# wiz16b8m4ct3_0_WIZ16B8M4CT3 register map
Vendor: Texas Instruments
Registers are 32-bit, read-write, reset 0x0 unless marked. A register's access mark holds for its fields unless they carry their own. Offsets are as the file gives them; [hi:lo] are bit positions; {n}, {i} and the like mark numbered series.

## wiz16b8m4ct3_0_WIZ16B8M4CT3 (part 7 of 12)
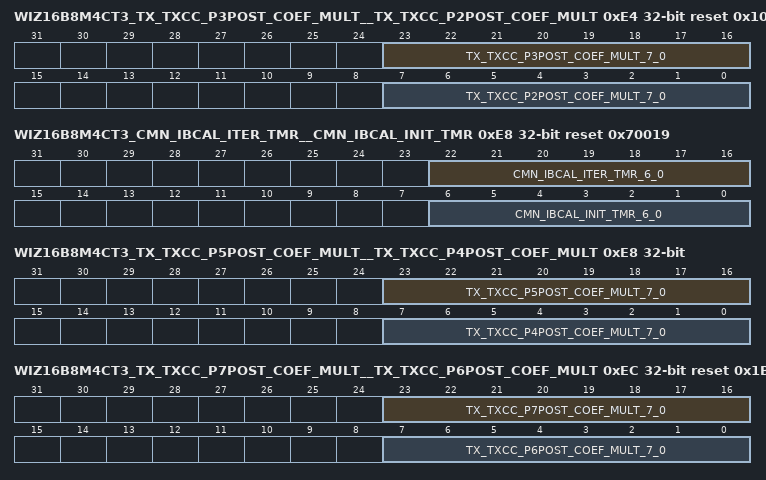
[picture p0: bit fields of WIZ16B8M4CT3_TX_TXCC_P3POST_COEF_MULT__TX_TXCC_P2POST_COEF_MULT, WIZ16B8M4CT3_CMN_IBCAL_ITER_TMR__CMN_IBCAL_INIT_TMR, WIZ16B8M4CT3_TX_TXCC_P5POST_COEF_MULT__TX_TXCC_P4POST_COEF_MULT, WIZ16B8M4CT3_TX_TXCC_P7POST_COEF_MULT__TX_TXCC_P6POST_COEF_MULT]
0xE4 WIZ16B8M4CT3_TX_TXCC_P3POST_COEF_MULT__TX_TXCC_P2POST_COEF_MULT reset 0x10001B
  [23:16] TX_TXCC_P3POST_COEF_MULT_7_0 — Preset 3 post emphasis coefficient multiplier value : The value in this field specifies the multiplier value used to generate the preset 3 post emphasis coefficient value from the FS value. The following describes the multiplier value each bit in this field corresponds to. Bit 7 : 128/128 = 1.000000 Bit 6 : 64/128 = 0.500000 Bit 5 : 32/128 = 0.250000 Bit 4 : 16/128 = 0.125000 Bit 3 : 8/128 = 0.062500 Bit 2 : 4/128 = 0.031250 Bit 1 : 2/128 = 0.015625 Bit 0 : 1/128 = 0.0078125 Note: The output of the multiplier is 6 bits wide. It is possible to set the multiplier value here to a sufficiently large value to cause the multiplier result to be such that it can't be represented by a 6 bit value. In such a case, the multiplier output will be driven to 6'b111111.
  [7:0] TX_TXCC_P2POST_COEF_MULT_7_0 — Preset 2 post emphasis coefficient multiplier value : The value in this field specifies the multiplier value used to generate the preset 2 post emphasis coefficient value from the FS value. The following describes the multiplier value each bit in this field corresponds to. Bit 7 : 128/128 = 1.000000 Bit 6 : 64/128 = 0.500000 Bit 5 : 32/128 = 0.250000 Bit 4 : 16/128 = 0.125000 Bit 3 : 8/128 = 0.062500 Bit 2 : 4/128 = 0.031250 Bit 1 : 2/128 = 0.015625 Bit 0 : 1/128 = 0.0078125 Note: The output of the multiplier is 6 bits wide. It is possible to set the multiplier value here to a sufficiently large value to cause the multiplier result to be such that it can't be represented by a 6 bit value. In such a case, the multiplier output will be driven to 6'b111111.
0xE8 WIZ16B8M4CT3_CMN_IBCAL_ITER_TMR__CMN_IBCAL_INIT_TMR reset 0x70019
  [22:16] CMN_IBCAL_ITER_TMR_6_0 — Iteration wait timer value: This is the number of cmn_ref_clk clocks to wait between when a value is placed on the calibration selection bus going to the analog, and when the comparator value coming from the analog circuits can be checked. Note: This should never be set to a value of less than 3.
  [6:0] CMN_IBCAL_INIT_TMR_6_0 — Initialization wait timer value: This is the number of cmn_ref_clk clocks to wait between when the analog calibration circuits are enabled, and when the first calibration selection value is placed on the calibration code bus, going to the analog. Note: This results in the minimum number of cmn_ref_clk clocks required to wait 1 uSec. Note: This should never be set to a value of less than 1.
0xE8 WIZ16B8M4CT3_TX_TXCC_P5POST_COEF_MULT__TX_TXCC_P4POST_COEF_MULT
  [23:16] TX_TXCC_P5POST_COEF_MULT_7_0 — Preset 5 post emphasis coefficient multiplier value : The value in this field specifies the multiplier value used to generate the preset 5 post emphasis coefficient value from the FS value. The following describes the multiplier value each bit in this field corresponds to. Bit 7 : 128/128 = 1.000000 Bit 6 : 64/128 = 0.500000 Bit 5 : 32/128 = 0.250000 Bit 4 : 16/128 = 0.125000 Bit 3 : 8/128 = 0.062500 Bit 2 : 4/128 = 0.031250 Bit 1 : 2/128 = 0.015625 Bit 0 : 1/128 = 0.0078125 Note: The output of the multiplier is 6 bits wide. It is possible to set the multiplier value here to a sufficiently large value to cause the multiplier result to be such that it can't be represented by a 6 bit value. In such a case, the multiplier output will be driven to 6'b111111.
  [7:0] TX_TXCC_P4POST_COEF_MULT_7_0 — Preset 4 post emphasis coefficient multiplier value : The value in this field specifies the multiplier value used to generate the preset 4 post emphasis coefficient value from the FS value. The following describes the multiplier value each bit in this field corresponds to. Bit 7 : 128/128 = 1.000000 Bit 6 : 64/128 = 0.500000 Bit 5 : 32/128 = 0.250000 Bit 4 : 16/128 = 0.125000 Bit 3 : 8/128 = 0.062500 Bit 2 : 4/128 = 0.031250 Bit 1 : 2/128 = 0.015625 Bit 0 : 1/128 = 0.0078125 Note: The output of the multiplier is 6 bits wide. It is possible to set the multiplier value here to a sufficiently large value to cause the multiplier result to be such that it can't be represented by a 6 bit value. In such a case, the multiplier output will be driven to 6'b111111.
0xEC WIZ16B8M4CT3_TX_TXCC_P7POST_COEF_MULT__TX_TXCC_P6POST_COEF_MULT reset 0x1B0000
  [23:16] TX_TXCC_P7POST_COEF_MULT_7_0 — Preset 7 post emphasis coefficient multiplier value : The value in this field specifies the multiplier value used to generate the preset 7 post emphasis coefficient value from the FS value. The following describes the multiplier value each bit in this field corresponds to. Bit 7 : 128/128 = 1.000000 Bit 6 : 64/128 = 0.500000 Bit 5 : 32/128 = 0.250000 Bit 4 : 16/128 = 0.125000 Bit 3 : 8/128 = 0.062500 Bit 2 : 4/128 = 0.031250 Bit 1 : 2/128 = 0.015625 Bit 0 : 1/128 = 0.0078125 Note: The output of the multiplier is 6 bits wide. It is possible to set the multiplier value here to a sufficiently large value to cause the multiplier result to be such that it can't be represented by a 6 bit value. In such a case, the multiplier output will be driven to 6'b111111.
  [7:0] TX_TXCC_P6POST_COEF_MULT_7_0 — Preset 6 post emphasis coefficient multiplier value : The value in this field specifies the multiplier value used to generate the preset 6 post emphasis coefficient value from the FS value. The following describes the multiplier value each bit in this field corresponds to. Bit 7 : 128/128 = 1.000000 Bit 6 : 64/128 = 0.500000 Bit 5 : 32/128 = 0.250000 Bit 4 : 16/128 = 0.125000 Bit 3 : 8/128 = 0.062500 Bit 2 : 4/128 = 0.031250 Bit 1 : 2/128 = 0.015625 Bit 0 : 1/128 = 0.0078125 Note: The output of the multiplier is 6 bits wide. It is possible to set the multiplier value here to a sufficiently large value to cause the multiplier result to be such that it can't be represented by a 6 bit value. In such a case, the multiplier output will be driven to 6'b111111.
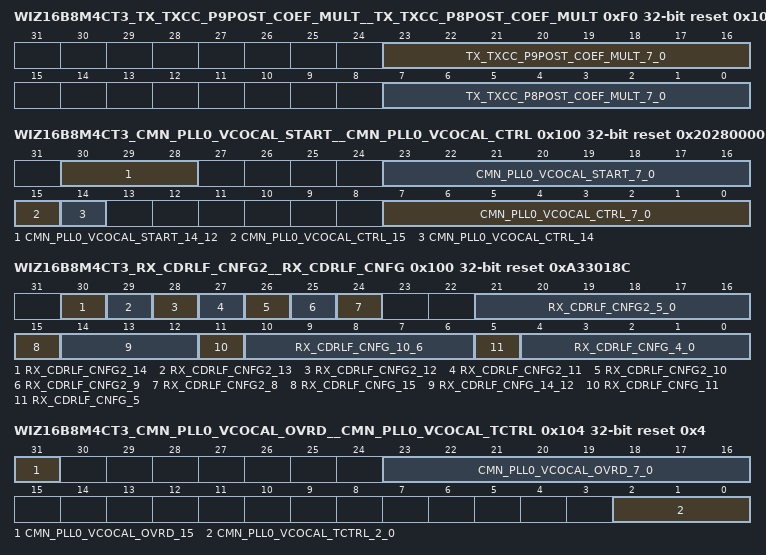
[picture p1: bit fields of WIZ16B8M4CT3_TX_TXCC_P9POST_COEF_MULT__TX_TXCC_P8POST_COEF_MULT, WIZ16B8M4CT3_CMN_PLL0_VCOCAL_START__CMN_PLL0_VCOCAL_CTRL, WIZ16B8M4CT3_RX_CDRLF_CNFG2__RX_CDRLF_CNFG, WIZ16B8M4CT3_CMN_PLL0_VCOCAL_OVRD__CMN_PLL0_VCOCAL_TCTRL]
0xF0 WIZ16B8M4CT3_TX_TXCC_P9POST_COEF_MULT__TX_TXCC_P8POST_COEF_MULT reset 0x10
  [23:16] TX_TXCC_P9POST_COEF_MULT_7_0 — Preset 9 post emphasis coefficient multiplier value : The value in this field specifies the multiplier value used to generate the preset 9 post emphasis coefficient value from the FS value. The following describes the multiplier value each bit in this field corresponds to. Bit 7 : 128/128 = 1.000000 Bit 6 : 64/128 = 0.500000 Bit 5 : 32/128 = 0.250000 Bit 4 : 16/128 = 0.125000 Bit 3 : 8/128 = 0.062500 Bit 2 : 4/128 = 0.031250 Bit 1 : 2/128 = 0.015625 Bit 0 : 1/128 = 0.0078125 Note: The output of the multiplier is 6 bits wide. It is possible to set the multiplier value here to a sufficiently large value to cause the multiplier result to be such that it can't be represented by a 6 bit value. In such a case, the multiplier output will be driven to 6'b111111.
  [7:0] TX_TXCC_P8POST_COEF_MULT_7_0 — Preset 8 post emphasis coefficient multiplier value : The value in this field specifies the multiplier value used to generate the preset 8 post emphasis coefficient value from the FS value. The following describes the multiplier value each bit in this field corresponds to. Bit 7 : 128/128 = 1.000000 Bit 6 : 64/128 = 0.500000 Bit 5 : 32/128 = 0.250000 Bit 4 : 16/128 = 0.125000 Bit 3 : 8/128 = 0.062500 Bit 2 : 4/128 = 0.031250 Bit 1 : 2/128 = 0.015625 Bit 0 : 1/128 = 0.0078125 Note: The output of the multiplier is 6 bits wide. It is possible to set the multiplier value here to a sufficiently large value to cause the multiplier result to be such that it can't be represented by a 6 bit value. In such a case, the multiplier output will be driven to 6'b111111.
0x100 WIZ16B8M4CT3_CMN_PLL0_VCOCAL_START__CMN_PLL0_VCOCAL_CTRL access per field reset 0x20280000
  [30:28] CMN_PLL0_VCOCAL_START_14_12 rw — VCO calibration initial step size control: This field specifies the initial step size for the VCO calibration state machine. The following are the values that can be used in this field, and the corresponding step sizes. 3'b000 : 1 3'b001 : 2 3'b010 : 4 3'b011 : 8 3'b100 : 16 3'b101 - 3'b111 : Reserved
  [23:16] CMN_PLL0_VCOCAL_START_7_0 rw — VCO calibration code starting point value: This field specifies the starting VCO code that is used by the VCO calibration state machine. The purpose of this value is such that the VCO calibration process starts at a point that is, on average, relatively close to the final calibration point. This allows the calibration time to be reduced, on average. The encoding of this field is the same as what is described in the VCO calibration control register. Note: This field is intended to be for diagnostics purposes only. Note : This field must be set to a value that is always at least one step size away from the minimum and maximum calibration codes, and is a function of the step size specified in this register. For example, if the initial step size is 4, this value must be at least 4 greater than the minimum calibration code or 4 less than the maximum calibration code.
  [15] CMN_PLL0_VCOCAL_CTRL_15 rw — Start VCO calibration: Activating (1'b1) this bit will start a VCO calibration process. This bit must remain active until the VCO calibration process is complete (as indicated by the VCO calibration process done bit in this register). To start another VCO calibration process, the VCO calibration process done bit must have gone inactive from any prior calibration process. Note: This bit is intended to be for diagnostics purposes only. This calibration process is automatically activated internally by the PLL control state machine. When using this bit, the user must wait until after the internally activated process completes.
  [14] CMN_PLL0_VCOCAL_CTRL_14 ro — VCO calibration process done: This bit will be set to 1'b1 when the VCO calibration process is complete. It will be cleared by the deactivation of the Start VCO calibration bit in this register. Note: This bit is intended to be for diagnostics purposes only. Note: This bit is not likely to be observed as being set after internal automatic calibration is complete, because the internally generated run signal will be driven inactive immediately after the done signal is activated, and therefore the internal done signal will be cleared.
  [7:0] CMN_PLL0_VCOCAL_CTRL_7_0 ro — VCO calibration code: This is the calibration code that was determined by the VCO calibration process. This signal is valid when the VCO calibration process is complete. The values of this field correspond to different frequency bands the VCO will operate in. The frequency bands are controlled by the number of capacitors that are switched in the VCO analog circuit. This field specifies the number of capacitors that are switched in. The following are the values for this code: 8'b00000000: 0 Capacitors activated 8'b00000001: 1 Capacitor activated 8'b00000010: 2 Capacitors activated 8'b00000011: 3 Capacitors activated ... 8'b11111110: 254 Capacitors activated 8'b11111111: 255 Capacitors activated Note: This register is intended to be for diagnostics purposes only. Note: The reset value for this field is with the PLL controller power island switched off. In cases where this power island is switched on, the reset value be 8'h28.
0x100 WIZ16B8M4CT3_RX_CDRLF_CNFG2__RX_CDRLF_CNFG access per field reset 0xA33018C
  [30] RX_CDRLF_CNFG2_14 rw — CDRLF second order loop integrator max clear enable: This signal enables the function in the CDRLF where the second order loop integrator is cleared when it reaches the maximum value.
  [29] RX_CDRLF_CNFG2_13 ro — CDRLF fast phase lock locked detected: This register bit is the current status of the fphl_locked pin on the CDRLF, and indicates the fast phase lock process is complete.
  [28] RX_CDRLF_CNFG2_12 rw — CDRLF fast phase lock diagnostic enable: This register bit can control the fphl_start pin on the CDRLF. for diagnostic purposes. If the CDRLF fast phase lock enabled by signal detect bit in this register is enabled, then either signal detect or this bit will activate the fphl_start pin.
  [27] RX_CDRLF_CNFG2_11 rw — CDRLF fast phase lock enabled by signal detect: When active, signal detect will control the fphl_start pin on the CDRLF. This will cause fast phase lock to be enabled whenever the macro detects a transition from electrical idle to high speed data.
  [26] RX_CDRLF_CNFG2_10 rw — CDRLF reset on CDRLF PM Accumulator Max: Activating (1'b1) this bit will force the CDRLF to be reset when the PM accumulator in the CDRLF reaches is maximum absolute value (the largest positive or negative value).
  [25] RX_CDRLF_CNFG2_9 rw — CDRLF freeze on electrical idle detect: Activating (1'b1) this bit will force the CDRLF to be freeze in its current state when the receiver signal detect detects an electrical idle. When high speed data is detected, the freeze will be released.
  [24] RX_CDRLF_CNFG2_8 rw — CDRLF reset on electrical idle detect: Activating (1'b1) this bit will force the CDRLF to be reset when the receiver signal detect detects an electrical idle. When high speed data is detected, the reset will be released.
  [21:16] RX_CDRLF_CNFG2_5_0 rw — CDRLF second order loop integrator threshold : This value is the maximum magnitude the CDRLF second order loop integrator will be allowed to go to. Note: This field must never be set to a value less than 2 (6'b000010).
  [15] RX_CDRLF_CNFG_15 rw — CDLRF reset hold: When active (1'b1), the CDRLF will be held in reset beyond the time that it would normally be released by its asynchronous release signals. The CDRLF will be held in reset until this bit is deactivated (1'b0). Note: This signal is intended be for verification purposes only. It should be set to 1'b0 for normal operation.
  [14:12] RX_CDRLF_CNFG_14_12 rw — CDRLF diagnostic mode control: This field controls the information driven on the rx_pi_val_ln_{15:0}[7:0] signal, when in diagnostics mode.
  [11] RX_CDRLF_CNFG_11 rw — CDRLF second order loop disable: Activating (1'b1) this bit will disable the CDRLF second order loop. Note: This signal is intended be for verification purposes only. It should be set to 1'b0 for normal operation.
  [10:6] RX_CDRLF_CNFG_10_6 rw — CDRLF second order loop sigma delta update rate: This is the value that is added to or subtracted from the second order loop accumulator register when the serial data sample clock is detected as being out of phase with the serial data on a given parallel data word cycle. This is part of the CDRLF averaging function.
  [5] RX_CDRLF_CNFG_5 rw — CDRLF first order loop disable: Activating (1'b1) this bit will disable the CDRLF first order loop. Note: This signal is intended to be for verification purposes only. It should be set to 1'b0 for normal operation.
  [4:0] RX_CDRLF_CNFG_4_0 rw — CDRLF first order loop sigma delta update rate: This is the value that is added to or subtracted from the first order loop accumulator register when the serial data sample clock is detected as being out of phase with the serial data on a given parallel data word cycle. This is part of the CDRLF averaging function.
0x104 WIZ16B8M4CT3_CMN_PLL0_VCOCAL_OVRD__CMN_PLL0_VCOCAL_TCTRL reset 0x4
  [31] CMN_PLL0_VCOCAL_OVRD_15 — VCO calibration code override enable: Activating (1'b1) this bit allows the VCO code determined during the automatic VCO calibration process to be overridden by the value driven by the VCO calibration code override value field in this register. Note: This bit is intended to be for diagnostics purposes only.
  [23:16] CMN_PLL0_VCOCAL_OVRD_7_0 — VCO calibration code override value: This field is used to override the VCO code determined during the automatic VCO calibration process. The VCO code driven on this field is valid when the VCO calibration code override enable bit in this register is active. The encoding of this field is the same as what is described in the VCO calibration control register.
  [2:0] CMN_PLL0_VCOCAL_TCTRL_2_0 — VCO calibration initial time scale control: This field specifies the calibration start time scaling factor applied to the VCO calibration when running the initial step size for the calibration code if not set to 1. Setting this value to a value other than 1 will reduce the calibration measurement time by the amount specified below. Then when the final calibration steps are made the full calibration time will be used to get the appropriate amount of resolution. 3'b000 : Div 1 3'b001 : Div 2 3'b010 : Div 4 3'b011 : Div 8 3'b100 : Div 16 3'b101 : Div 32 3'b110 : Div 64 3'b111 : Div 128
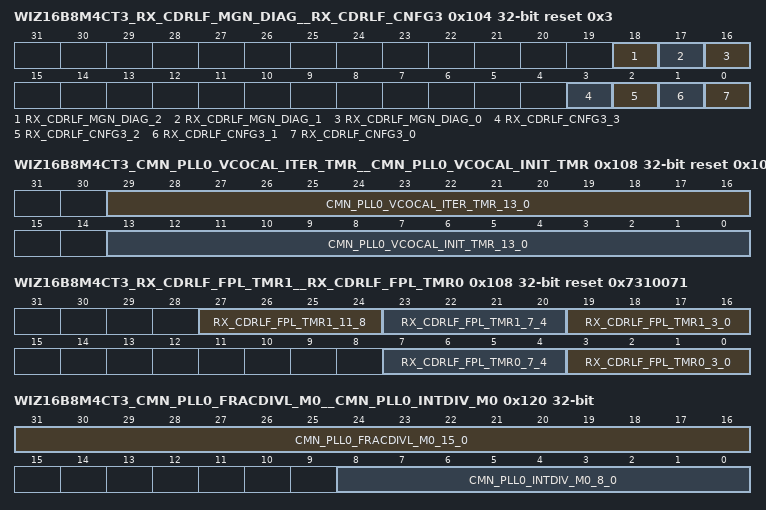
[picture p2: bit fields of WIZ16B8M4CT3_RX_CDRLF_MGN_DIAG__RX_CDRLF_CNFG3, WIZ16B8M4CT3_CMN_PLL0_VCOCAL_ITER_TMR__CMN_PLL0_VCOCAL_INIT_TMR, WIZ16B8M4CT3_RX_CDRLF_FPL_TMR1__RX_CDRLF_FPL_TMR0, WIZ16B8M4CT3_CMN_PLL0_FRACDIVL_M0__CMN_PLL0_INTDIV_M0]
0x104 WIZ16B8M4CT3_RX_CDRLF_MGN_DIAG__RX_CDRLF_CNFG3 access per field reset 0x3
  [18] RX_CDRLF_MGN_DIAG_2 wo — CDRLF PI override down : When the CDRLF PI override enable function is enabled, writing a 1'b1 to this bit will force a down to be generated in the CDRLF PI interface logic. Note : This bit will be automatically cleared after the down request has been sent to the CDRLF PI interface logic. The down request is generated by changing the state of the cdrlf_pi_down_in signal in the CDRLF.
  [17] RX_CDRLF_MGN_DIAG_1 wo — CDRLF PI override up : When the CDRLF PI override enable function is enabled, writing a 1'b1 to this bit will force an up to be generated in the CDRLF PI interface logic. Note : This bit will be automatically cleared after the up request has been sent to the CDRLF PI interface logic. The up request is generated by changing the state of the cdrlf_pi_up_in signal in the CDRLF.
  [16] RX_CDRLF_MGN_DIAG_0 rw — CDRLF PI override enable : Setting this bit to 1'b1 will enable the CDRLF PI override function, which will allow ups and downs to be forced to the CDRLF PI interface logic from the up and down override bits in this register. Note : This bit must be set to 1'b1 before the CDRLF PI override up and down bits in this register are changed.
  [3] RX_CDRLF_CNFG3_3 rw — CDRLF data filter enable standard mode 3 : Enables the filter function for the data that feeds into the CDRLF from the deserializer, using the rxda_cdrlf_data_filter_en_n signal, when xcvr_standard_mode is set to 2'b11. 1'b0 : Enable filter of 1010 patterns from the CDRLF. 1'b1 : No CDRLF data filter function enabled.
  [2] RX_CDRLF_CNFG3_2 rw — CDRLF data filter enable standard mode 2 : Enables the filter function for the data that feeds into the CDRLF from the deserializer, using the rxda_cdrlf_data_filter_en_n signal, when xcvr_standard_mode is set to 2'b10. 1'b0 : Enable filter of 1010 patterns from the CDRLF. 1'b1 : No CDRLF data filter function enabled.
  [1] RX_CDRLF_CNFG3_1 rw — CDRLF data filter enable standard mode 1 : Enables the filter function for the data that feeds into the CDRLF from the deserializer, using the rxda_cdrlf_data_filter_en_n signal, when xcvr_standard_mode is set to 2'b01. 1'b0 : Enable filter of 1010 patterns from the CDRLF. 1'b1 : No CDRLF data filter function enabled.
  [0] RX_CDRLF_CNFG3_0 rw — CDRLF data filter enable standard mode 0 : Enables the filter function for the data that feeds into the CDRLF from the deserializer, using the rxda_cdrlf_data_filter_en_n signal, when xcvr_standard_mode is set to 2'b00. 1'b0 : Enable filter of 1010 patterns from the CDRLF. 1'b1 : No CDRLF data filter function enabled.
0x108 WIZ16B8M4CT3_CMN_PLL0_VCOCAL_ITER_TMR__CMN_PLL0_VCOCAL_INIT_TMR reset 0x1003E8
  [29:16] CMN_PLL0_VCOCAL_ITER_TMR_13_0 — Iteration wait timer value: This is the number of clocks to wait between when a calibration code is driven to the analog, and when the clock rates are measured.
  [13:0] CMN_PLL0_VCOCAL_INIT_TMR_13_0 — Initialization wait timer value: This is the number of clocks to wait between when the analog VCO calibration circuits are enabled, and when the first calibration code is driven to the analog. Note: This results in the minimum number of cmn_ref_clk clocks required to wait 10 uSec.
0x108 WIZ16B8M4CT3_RX_CDRLF_FPL_TMR1__RX_CDRLF_FPL_TMR0 reset 0x7310071
  [27:24] RX_CDRLF_FPL_TMR1_11_8 — Fast phase lock timer trigger 1 state time value : Specifies the number of clock cycles minus 1 that the fast phase lock state machine will remain in the trigger state the first time it is in that state. The recommended value for this is the number of PI steps required to move the PI 1/4 UI.
  [23:20] RX_CDRLF_FPL_TMR1_7_4 — Fast phase lock timer trigger 2 state time value : Specifies the number of clock cycles minus 1 that the fast phase lock state machine will remain in the trigger state the second time it is in that state. The recommended value for this is the number of PI steps required to move the PI 1/8 UI.
  [19:16] RX_CDRLF_FPL_TMR1_3_0 — Fast phase lock timer trigger 3 state time value : Specifies the number of clock cycles minus 1 that the fast phase lock state machine will remain in the trigger state the third time it is in that state. The recommended value for this is the number of PI steps required to move the PI 1/16 UI.
  [7:4] RX_CDRLF_FPL_TMR0_7_4 — Fast phase lock timer accumulate state time value : Specifies the number of clock cycles minus 1 that the fast phase lock state machine will remain in the accumulate state.
  [3:0] RX_CDRLF_FPL_TMR0_3_0 — Fast phase lock timer delay state time value : Specifies the number of clock cycles minus 1 that the fast phase lock state machine will remain in the delay state.
0x10C WIZ16B8M4CT3_CMN_PLL0_VCOCAL_REFTIM_START reset 0xC5F
  [13:0] CMN_PLL0_VCOCAL_REFTIM_START_13_0 — PLL VCO calibration reference clock timer start value : This is the value that is loaded into the reference clock timer as the starting point for that timer, when running VCO calibration. The value in this field must correspond to a time that is approximately one full spread spectrum cycle long (31.67 uSec) Note: The actual number of clocks counted is one larger than what is specified by this field.
0x110 WIZ16B8M4CT3_CMN_PLL0_VCOCAL_PLLCNT_START reset 0xC5F
  [13:0] CMN_PLL0_VCOCAL_PLLCNT_START_13_0 — PLL VCO calibration PLL clock counter start value : This is the value that is loaded into the PLL clock counter as the starting point for that counter, when running VCO calibration. When programming this register, it is important to understand how the frequency of the cmnda_pll0_fb_divider_clk is calculated relative to the reference clock. This is described in section 10.4 Dual VCO PLL on page 411. Note: The actual number of clocks counted is one larger than what is specified by this field.
0x120 WIZ16B8M4CT3_CMN_PLL0_FRACDIVL_M0__CMN_PLL0_INTDIV_M0
  [31:16] CMN_PLL0_FRACDIVL_M0_15_0 — pll_fb_div_fractional: Value of the pll_fb_div_fractional[15:0] signal.
  [8:0] CMN_PLL0_INTDIV_M0_8_0 — pll_fb_div_integer value: Value of the pll_fb_div_integer signal.
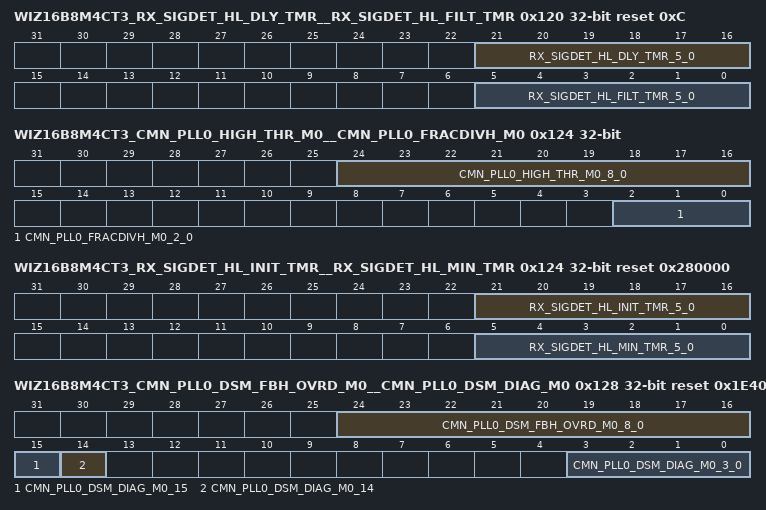
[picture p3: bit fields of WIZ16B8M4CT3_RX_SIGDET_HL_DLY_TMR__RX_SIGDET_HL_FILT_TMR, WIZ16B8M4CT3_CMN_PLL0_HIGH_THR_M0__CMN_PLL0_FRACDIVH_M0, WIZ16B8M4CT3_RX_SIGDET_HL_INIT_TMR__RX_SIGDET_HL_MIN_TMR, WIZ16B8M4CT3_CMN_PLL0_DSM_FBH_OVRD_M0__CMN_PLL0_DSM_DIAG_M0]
0x120 WIZ16B8M4CT3_RX_SIGDET_HL_DLY_TMR__RX_SIGDET_HL_FILT_TMR reset 0xC
  [21:16] RX_SIGDET_HL_DLY_TMR_5_0 — Signal detect filter high to low delay timer value: This is the value loaded into the delay timer in the signal detect high to low filter circuit.
  [5:0] RX_SIGDET_HL_FILT_TMR_5_0 — Signal detect filter high to low filter timer value: This is the value loaded into the filter timer in the signal detect high to low filter circuit.
0x124 WIZ16B8M4CT3_CMN_PLL0_HIGH_THR_M0__CMN_PLL0_FRACDIVH_M0
  [24:16] CMN_PLL0_HIGH_THR_M0_8_0 — pll_fb_div_high_theshold: Value of the pll_fb_div_high_threshold signal. The value of this register should be 2/3 the value of the combined integer and fractional divider values, and rounded up to the next even number.
  [2:0] CMN_PLL0_FRACDIVH_M0_2_0 — pll_fb_div_fractional: Value of the pll_fb_div_fractional[18:16] signal.
0x124 WIZ16B8M4CT3_RX_SIGDET_HL_INIT_TMR__RX_SIGDET_HL_MIN_TMR reset 0x280000
  [21:16] RX_SIGDET_HL_INIT_TMR_5_0 — Signal detect init timer value: This is the value loaded into the initialization timer in the signal detect filter high to low filter circuit.
  [5:0] RX_SIGDET_HL_MIN_TMR_5_0 — Signal detect filter high to low min timer value: This is the value loaded into the min timer in the signal detect high to low filter circuit.
0x128 WIZ16B8M4CT3_CMN_PLL0_DSM_FBH_OVRD_M0__CMN_PLL0_DSM_DIAG_M0 reset 0x1E4004
  [24:16] CMN_PLL0_DSM_FBH_OVRD_M0_8_0 — PLL feedback divider high override value : When enabled by the PLL feedback divider override enable bit in the PLL 0 delta sigma modulator diagnostics register mode 0 on page 117, the value in this field will be used to override the value on the cmnda_pll0_fb_div_high signal. Note: The value of this register should be 2/3 the value of the combined PLL feedback divider high and low values, and rounded up to the next even number.
  [15] CMN_PLL0_DSM_DIAG_M0_15 — Delta sigma bypass enable: When set to 1'b1, the delta sigma modulator will be bypassed, and the output will be the value specified for the internal pll_fb_div_integer signal.
  [14] CMN_PLL0_DSM_DIAG_M0_14 — PLL feedback divider override enable : When active (1'b1), the feedback divider low and high override values in the PLL 0 delta sigma modulator feedback divider value high override register mode 0 on page 117 and PLL 0 delta sigma modulator feedback divider value low override register mode 0 on page 117 registers will be used to override the feedback divider values driven to the analog.
  [3:0] CMN_PLL0_DSM_DIAG_M0_3_0 — PLL feedback divider latency adjustment: This signal specifies a value to be subtracted from the feedback divider settings before they are output on the cmnda_pll0_fb_div_high and cmnda_pll0_fb_div_low signals.
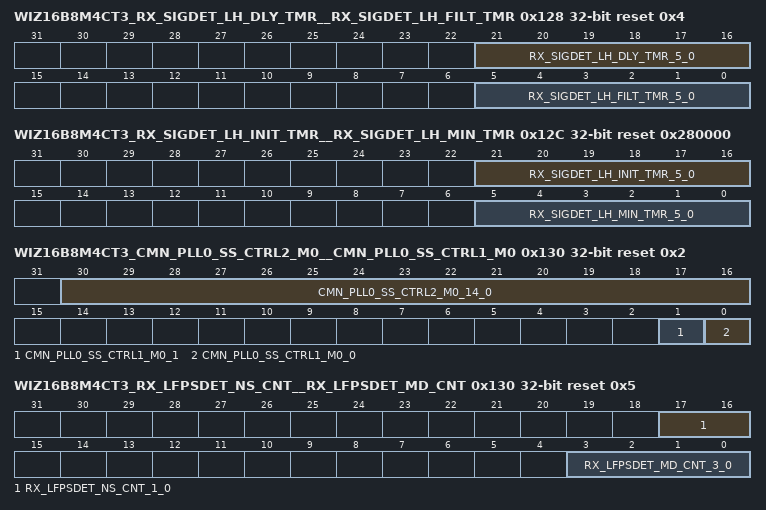
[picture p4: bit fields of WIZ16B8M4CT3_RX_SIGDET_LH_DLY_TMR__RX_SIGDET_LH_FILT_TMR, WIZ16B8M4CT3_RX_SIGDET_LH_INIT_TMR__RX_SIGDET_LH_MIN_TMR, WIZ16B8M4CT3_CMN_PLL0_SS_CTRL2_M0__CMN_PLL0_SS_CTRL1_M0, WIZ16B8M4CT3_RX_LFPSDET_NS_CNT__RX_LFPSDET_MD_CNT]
0x128 WIZ16B8M4CT3_RX_SIGDET_LH_DLY_TMR__RX_SIGDET_LH_FILT_TMR reset 0x4
  [21:16] RX_SIGDET_LH_DLY_TMR_5_0 — Signal detect filter low to high min timer value: This is the value loaded into the min timer in the signal detect low to high filter circuit.
  [5:0] RX_SIGDET_LH_FILT_TMR_5_0 — Signal detect filter low to high filter timer value: This is the value loaded into the filter timer in the signal detect low to high filter circuit. This should be set to 5 less than the number of clocks of desired filter time. This takes into account the synchronizing of the signal to be filtered (4 clocks) and the time to load the filter timer (1 clock). Therefore, the smallest granularity of filtering available here is 5 clocks. This is more of an issue of latency through the filter circuit as the signal initially rises.
0x12C WIZ16B8M4CT3_CMN_PLL0_DSM_FBL_OVRD_M0 reset 0xC
  [8:0] CMN_PLL0_DSM_FBL_OVRD_M0_8_0 — PLL feedback divider low override value : When enabled by the PLL feedback divider override enable bit in the PLL 0 delta sigma modulator diagnostics register mode 0 on page 117, the value in this field will be used to override the value on the cmnda_pll0_fb_div_low signal.
0x12C WIZ16B8M4CT3_RX_SIGDET_LH_INIT_TMR__RX_SIGDET_LH_MIN_TMR reset 0x280000
  [21:16] RX_SIGDET_LH_INIT_TMR_5_0 — Signal detect init timer value: This is the value loaded into the initialization timer in the signal detect filter high to low filter circuit.
  [5:0] RX_SIGDET_LH_MIN_TMR_5_0 — Signal detect filter high to low min timer value: This is the value loaded into the min timer in the signal detect high to low filter circuit.
0x130 WIZ16B8M4CT3_CMN_PLL0_SS_CTRL2_M0__CMN_PLL0_SS_CTRL1_M0 reset 0x2
  [30:16] CMN_PLL0_SS_CTRL2_M0_14_0 — Amplitude step size: Value of the amplitude_step_size pin on the spread spectrum waveform generator. Note: This field should not be set to 0 when spread spectrum is enabled.
  [1] CMN_PLL0_SS_CTRL1_M0_1 — Spread spectrum waveform generator disable: Setting this bit to a 1'b1 will disable the spread spectrum waveform generator.
  [0] CMN_PLL0_SS_CTRL1_M0_0 — Spread spectrum enable during VCO calibration : Setting this bit to a 1'b1 will enable the spread spectrum function while VCO calibration is taking place.
0x130 WIZ16B8M4CT3_RX_LFPSDET_NS_CNT__RX_LFPSDET_MD_CNT reset 0x5
  [17:16] RX_LFPSDET_NS_CNT_1_0 — No signal counter value (NS): Specifies the number of clock cycles where pulse_high and pulse_low are inactive before declaring no signal. Note: a value of 2'b00 is not a valid value for this field.
  [3:0] RX_LFPSDET_MD_CNT_3_0 — Minimum pulse distance counter value (MD): Specifies the minimum pulse distance for a valid LFPS sequence. Note: MD must be set to a value that is greater than MP.
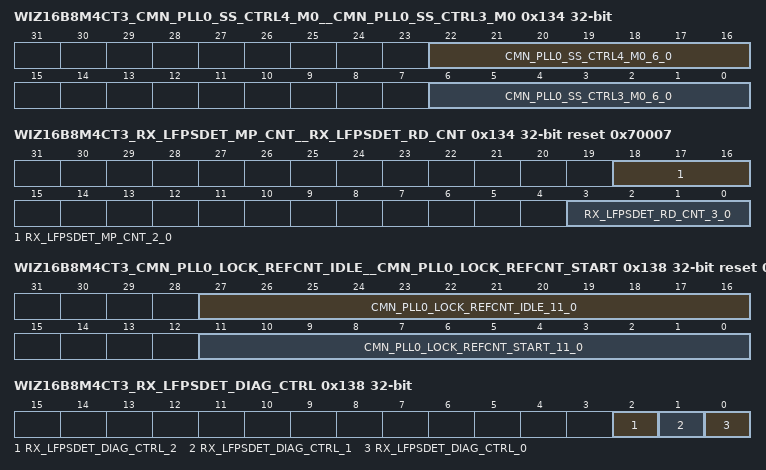
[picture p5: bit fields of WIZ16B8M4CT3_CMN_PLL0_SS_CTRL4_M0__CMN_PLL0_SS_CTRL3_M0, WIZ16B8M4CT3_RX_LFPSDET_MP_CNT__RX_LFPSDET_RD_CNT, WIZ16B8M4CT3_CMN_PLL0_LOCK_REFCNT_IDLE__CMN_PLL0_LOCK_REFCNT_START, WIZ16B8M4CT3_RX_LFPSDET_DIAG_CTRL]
0x134 WIZ16B8M4CT3_CMN_PLL0_SS_CTRL4_M0__CMN_PLL0_SS_CTRL3_M0
  [22:16] CMN_PLL0_SS_CTRL4_M0_6_0 — Time step size: Value for the time_step_size pin on the spread spectrum waveform generator. Note: This field should not be set to 0 when spread spectrum is enabled.
  [6:0] CMN_PLL0_SS_CTRL3_M0_6_0 — Number of steps: Value of the num_steps pin on the spread spectrum waveform generator. Note: This field should not be set to 0 when spread spectrum is enabled.
0x134 WIZ16B8M4CT3_RX_LFPSDET_MP_CNT__RX_LFPSDET_RD_CNT reset 0x70007
  [18:16] RX_LFPSDET_MP_CNT_2_0 — Minimum pulse duration (MP): Specifies the minimum number of clock cycles required for a given LFPS pulse to be driven active to be considered part of a valid LFPS burst.
  [3:0] RX_LFPSDET_RD_CNT_3_0 — Ramp down counter value (RD): Species the number of clock cycles that are used in the LFPS detect ramp down process. This signal should correspond to the MD, to reduce LFPS distortion. Note: The actual ramp down time is a function of the detection of no signal when lfps_detected is driven active. If no signal is detected, the ramp down time is the value in this field minus the value of the no signal counter value field in the RX_LFPSDET_NS_CNT register. Otherwise, the value in this field is used as is.
0x138 WIZ16B8M4CT3_CMN_PLL0_LOCK_REFCNT_IDLE__CMN_PLL0_LOCK_REFCNT_START reset 0x400C8
  [27:16] CMN_PLL0_LOCK_REFCNT_IDLE_11_0 — PLL lock reference counter idle value : This is the value used by the PLL lock detection logic to specify the number of reference clocks between each phase of counting PLL clocks.
  [11:0] CMN_PLL0_LOCK_REFCNT_START_11_0 — PLL lock reference counter start value : This is the value that is loaded into the PLL lock detect reference counter as the starting point for that counter, when checking for PLL lock. Note: The value required here is a function of the PLL feedback divider clock mode and the reference clock frequency. Overview information in regards to this can be found in section 4.2 Reference Clock Related Clocking and Reset on page 288 and section 4.9 Reference Clock Related Clock Rate Summary on page 319. The following bullet points specify the required time the value in this register is required to generate. By default, the value in this register is set for FBR mode with a 100 MHz reference clock. FBR mode and reference clock frequency greater than or equal to 100 MHz: 2 uSec FBR mode and reference clock frequency less than 100 MHz: 8 uSec DR mode: 800 nSec
0x138 WIZ16B8M4CT3_RX_LFPSDET_DIAG_CTRL
  [2] RX_LFPSDET_DIAG_CTRL_2 — Disable pulse none MD check: When active (1'b1), the check that tests if pulse_none is driven inactive while the MD check is being performed will be disabled.
  [1] RX_LFPSDET_DIAG_CTRL_1 — LFPS detect override enable: When active (1'b1), the LFPS detect override bit in this register will drive the LFPS detect output directly.
  [0] RX_LFPSDET_DIAG_CTRL_0 — LFPS detect override: When enabled by the LFPS detect override enable bit in this register, this bit will drive the LFPS detect output directly.
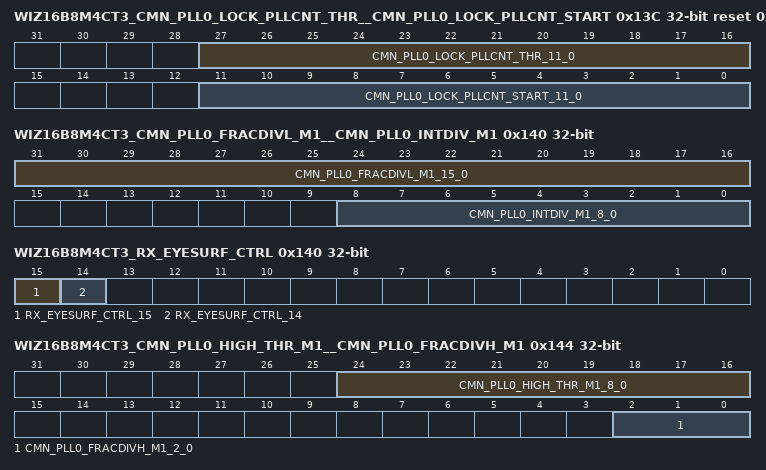
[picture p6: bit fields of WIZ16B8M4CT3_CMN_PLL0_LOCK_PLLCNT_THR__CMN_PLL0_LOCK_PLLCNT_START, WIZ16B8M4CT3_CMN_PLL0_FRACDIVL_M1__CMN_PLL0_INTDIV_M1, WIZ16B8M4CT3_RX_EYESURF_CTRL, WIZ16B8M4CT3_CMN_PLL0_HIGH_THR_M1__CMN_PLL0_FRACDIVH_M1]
0x13C WIZ16B8M4CT3_CMN_PLL0_LOCK_PLLCNT_THR__CMN_PLL0_LOCK_PLLCNT_START reset 0x300C8
  [27:16] CMN_PLL0_LOCK_PLLCNT_THR_11_0 — PLL lock counter threshold value : This is the value used by the PLL lock detection logic to determine if the PLL has locked. If the two counters in the PLL lock detection logic differ by less than this value, the PLL is considered locked.
  [11:0] CMN_PLL0_LOCK_PLLCNT_START_11_0 — PLL lock PLL counter start value : This is the value that is loaded into the PLL lock detect PLL counter as the starting point for that counter, when checking for PLL lock. The value is the number of PLL feedback divider clock edges that are expected during the time specified by the PLL 0 lock reference counter start value register on page 115. When programming this register, it is important to understand how the frequency of the cmnda_pll0_fb_divider_clk is calculated relative to the reference clock. This is described in section 10.4 Dual VCO PLL on page 411.
0x140 WIZ16B8M4CT3_CMN_PLL0_FRACDIVL_M1__CMN_PLL0_INTDIV_M1
  [31:16] CMN_PLL0_FRACDIVL_M1_15_0 — pll_fb_div_fractional: Value of the pll_fb_div_fractional[15:0] signal.
  [8:0] CMN_PLL0_INTDIV_M1_8_0 — pll_fb_div_integer value: Value of the pll_fb_div_integer signal.
0x140 WIZ16B8M4CT3_RX_EYESURF_CTRL access per field
  [15] RX_EYESURF_CTRL_15 rw — Eye surf run: Setting this bit to 1'b1 will initiate the eye surf process. This bit must remain set to 1'b1 until the eye surf done bit is set.
  [14] RX_EYESURF_CTRL_14 ro — Eye surf done: When this bit is set to 1'b1, the eye surf process has completed. This bit will be cleared after the eye surf run bit is cleared.
0x144 WIZ16B8M4CT3_CMN_PLL0_HIGH_THR_M1__CMN_PLL0_FRACDIVH_M1
  [24:16] CMN_PLL0_HIGH_THR_M1_8_0 — pll_fb_div_high_theshold: Value of the pll_fb_div_high_threshold signal. The value of this register should be 2/3 the value of the combined integer and fractional divider values, and rounded up to the next even number.
  [2:0] CMN_PLL0_FRACDIVH_M1_2_0 — pll_fb_div_fractional: Value of the pll_fb_div_fractional[18:16] signal.
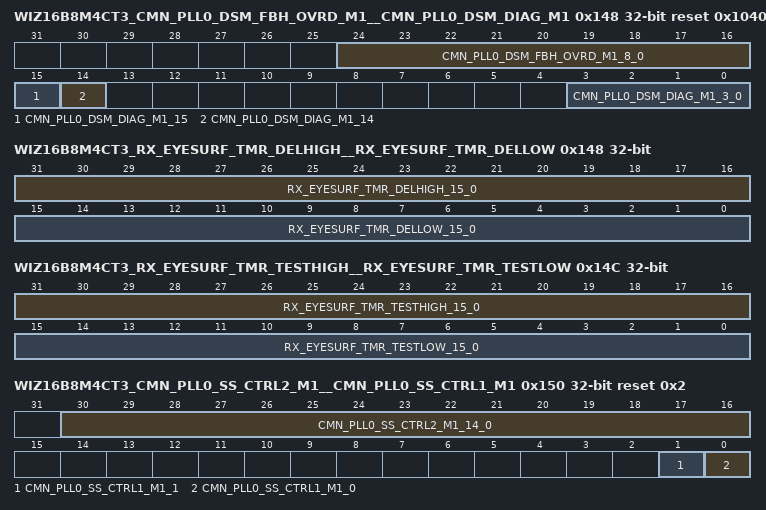
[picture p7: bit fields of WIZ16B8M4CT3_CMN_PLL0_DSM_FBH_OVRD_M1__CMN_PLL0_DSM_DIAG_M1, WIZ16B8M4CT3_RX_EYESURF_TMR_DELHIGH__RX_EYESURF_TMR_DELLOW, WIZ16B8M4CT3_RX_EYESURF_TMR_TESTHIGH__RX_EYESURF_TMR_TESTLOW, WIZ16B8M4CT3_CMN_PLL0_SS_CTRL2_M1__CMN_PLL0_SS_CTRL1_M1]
0x148 WIZ16B8M4CT3_CMN_PLL0_DSM_FBH_OVRD_M1__CMN_PLL0_DSM_DIAG_M1 reset 0x104004
  [24:16] CMN_PLL0_DSM_FBH_OVRD_M1_8_0 — PLL feedback divider high override value : When enabled by the PLL feedback divider override enable bit in the PLL 0 delta sigma modulator diagnostics register mode 0 on page 117, the value in this field will be used to override the value on the cmnda_pll0_fb_div_high signal. Note: The value of this register should be 2/3 the value of the combined PLL feedback divider high and low values, and rounded up to the next even number.
  [15] CMN_PLL0_DSM_DIAG_M1_15 — Delta sigma bypass enable: When set to 1'b1, the delta sigma modulator will be bypassed, and the output will be the value specified for the internal pll_fb_div_integer signal.
  [14] CMN_PLL0_DSM_DIAG_M1_14 — PLL feedback divider override enable : When active (1'b1), the feedback divider low and high override values in the PLL 0 delta sigma modulator feedback divider value high override register mode 0 on page 117 and PLL 0 delta sigma modulator feedback divider value low override register mode 0 on page 117 registers will be used to override the feedback divider values driven to the analog.
  [3:0] CMN_PLL0_DSM_DIAG_M1_3_0 — PLL feedback divider latency adjustment: This signal specifies a value to be subtracted from the feedback divider settings before they are output on the cmnda_pll0_fb_div_high and cmnda_pll0_fb_div_low signals.
0x148 WIZ16B8M4CT3_RX_EYESURF_TMR_DELHIGH__RX_EYESURF_TMR_DELLOW
  [31:16] RX_EYESURF_TMR_DELHIGH_15_0 — Most significant 16 bits of the delay time: The delay time specifies the number of clock cycles to wait between when a coordinate test point is set, and when to start testing the i and e data. Note : It is not valid to set the total eye surf timer delay value to 0.
  [15:0] RX_EYESURF_TMR_DELLOW_15_0 — Least significant 16 bits of the delay time: The delay time specifies the number of clock cycles to wait between when a coordinate test point is set, and when to start testing the i and e data. Note : It is not valid to set the total eye surf timer delay value to 0.
0x14C WIZ16B8M4CT3_CMN_PLL0_DSM_FBL_OVRD_M1 reset 0x10
  [8:0] CMN_PLL0_DSM_FBL_OVRD_M1_8_0 — PLL feedback divider low override value : When enabled by the PLL feedback divider override enable bit in the PLL 0 delta sigma modulator diagnostics register mode 0 on page 117, the value in this field will be used to override the value on the cmnda_pll0_fb_div_low signal.
0x14C WIZ16B8M4CT3_RX_EYESURF_TMR_TESTHIGH__RX_EYESURF_TMR_TESTLOW
  [31:16] RX_EYESURF_TMR_TESTHIGH_15_0 — Most significant 16 bits of the test time: The test time specifies the number of clock cycles to test the i and e data at a given coordinate test point. Note : It is not valid to set the total eye surf timer test value to 0.
  [15:0] RX_EYESURF_TMR_TESTLOW_15_0 — Least significant 16 bits of the test time: The test time specifies the number of clock cycles to test the i and e data at a given coordinate test point. Note : It is not valid to set the total eye surf timer test value to 0.
0x150 WIZ16B8M4CT3_CMN_PLL0_SS_CTRL2_M1__CMN_PLL0_SS_CTRL1_M1 reset 0x2
  [30:16] CMN_PLL0_SS_CTRL2_M1_14_0 — Amplitude step size: Value of the amplitude_step_size pin on the spread spectrum waveform generator. Note: This field should not be set to 0 when spread spectrum is enabled.
  [1] CMN_PLL0_SS_CTRL1_M1_1 — Spread spectrum waveform generator disable: Setting this bit to a 1'b1 will disable the spread spectrum waveform generator.
  [0] CMN_PLL0_SS_CTRL1_M1_0 — Spread spectrum enable during VCO calibration : Setting this bit to a 1'b1 will enable the spread spectrum function while VCO calibration is taking place.
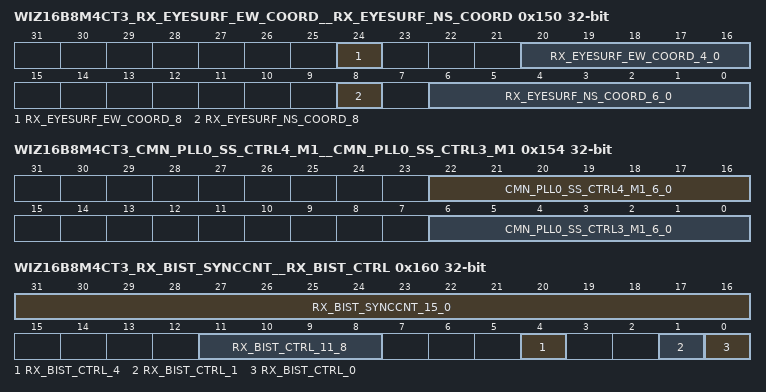
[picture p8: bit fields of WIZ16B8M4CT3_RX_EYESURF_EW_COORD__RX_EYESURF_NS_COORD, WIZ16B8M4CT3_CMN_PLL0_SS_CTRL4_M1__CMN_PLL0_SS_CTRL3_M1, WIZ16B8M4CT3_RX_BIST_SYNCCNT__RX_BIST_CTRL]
0x150 WIZ16B8M4CT3_RX_EYESURF_EW_COORD__RX_EYESURF_NS_COORD
  [24] RX_EYESURF_EW_COORD_8 — Test point coordinate east west direction : Indicates whether the desired test point is in the east or the west direction relative to the origin. 1b1 : East 1b0 : West
  [20:16] RX_EYESURF_EW_COORD_4_0 — Test point coordinate east west offset : Indicates how many steps in the east or west direction the desired test point is relative to the origin.
  [8] RX_EYESURF_NS_COORD_8 — Test point coordinate north south direction : Indicates whether the desired test point is in the north or the south direction relative to the origin. 1b1 : North 1b0 : South
  [6:0] RX_EYESURF_NS_COORD_6_0 — Test point coordinate north south offset : Indicates how many steps in the north or south direction the desired test point is relative to the origin. Note: In this implementation, only 5 least significant bits are used to control the sampler error DAC. Therefore, the most significant bits of this field are not used.
0x154 WIZ16B8M4CT3_CMN_PLL0_SS_CTRL4_M1__CMN_PLL0_SS_CTRL3_M1
  [22:16] CMN_PLL0_SS_CTRL4_M1_6_0 — Time step size: Value for the time_step_size pin on the spread spectrum waveform generator. Note: This field should not be set to 0 when spread spectrum is enabled.
  [6:0] CMN_PLL0_SS_CTRL3_M1_6_0 — Number of steps: Value of the num_steps pin on the spread spectrum waveform generator. Note: This field should not be set to 0 when spread spectrum is enabled.
0x154 WIZ16B8M4CT3_RX_EYESURF_ERRCNT ro
  [15:0] RX_EYESURF_ERRCNT_15_0 — Test point bit error count : The total number of bit errors that were detected for a given run of the eye surf function. This register is only valid after the eye surf done bit in the Eye surf control register (!) on page 305 is active, and will be cleared when the done bit is cleared in response to the run bit being cleared.
0x160 WIZ16B8M4CT3_RX_BIST_SYNCCNT__RX_BIST_CTRL access per field
  [31:16] RX_BIST_SYNCCNT_15_0 rw — Receiver BIST sync count: This field controls the value of the RX BIST sync count. The sync count indicates the number of consecutive received data words with no BIST bit errors that must be received in order for the RX BIST module to be considered synced to the input data stream. It is recommended that, when using a clean channel, this register be set to 16'h00FA. This will require the RX BIST to receive 250 consecutive words of data to confirm a BIST sync, which is enough time to allow the CDRLF to lock.
  [11:8] RX_BIST_CTRL_11_8 rw — Receiver BIST mode: Controls which mode the BIST will operate in. The value of this field must match the corresponding field for the receive BIST controller. The following are the values used for this field, and what BIST mode they correspond to. 4'b0000 : User defined data FIFO 4'b0001 - 4'b0111 : Reserved 4'b1000 : PRBS7 : 7 bit LFSR 4'b1001 : PRBS15 : 15 bit LFSR 4'b1010 : PRBS23 : 23 bit LFSR 4'b1011 : PRBS31 : 31 bit LFSR 4'b1100 - 4'b1111 : Reserved
  [4] RX_BIST_CTRL_4 rw — Receiver BIST error reset: Writing this bit is set to a 1'b1 will hold the error indicators in the receive BIST logic in reset. When this signal goes active, the rx_bist_status pin, rx_bist_err_toggle pin, and receive BIST error count field in this register will be cleared. When this bit is cleared, these error indicators will be released from reset and operate normally.
  [1] RX_BIST_CTRL_1 wo — Receiver BIST user defined data FIFO clear: Writing a 1'b1 to this bit will clear the receiver BIST user defined data FIFO. Note : This bit is automatically cleared after it is written to. Note : This clear function simply resets the FIFO pointers. It does not clear the contents of the FIFO.
  [0] RX_BIST_CTRL_0 rw — Receiver BIST enable: This bit enables the receiver BIST function. Note : The remaining bits in this register must be stable when changing this bit. Therefore, it is best to enable and disable this function using a read / modify / write of this bit.
